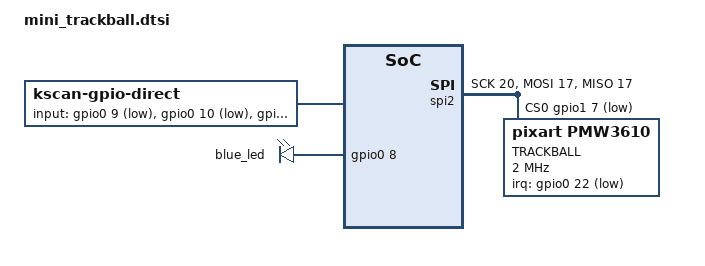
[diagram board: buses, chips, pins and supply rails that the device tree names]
/*
 * Copyright (c) 2020 The ZMK Contributors
 *
 * SPDX-License-Identifier: MIT
 */

#include <dt-bindings/zmk/matrix_transform.h>

/* blade-specific: common settings */ 
/ {

	chosen: chosen {
		zmk,kscan = &kscan;
		zmk,matrix_transform = &default_transform;
	};

/* global matrix transform */
	default_transform: keymap_transform_0 {
		compatible = "zmk,matrix-transform";
		columns = <4>;
		rows = <1>;
		map = <
RC(0,0) RC(0,1) RC(0,2) RC(0,3)
		>;

	};

  /* Scan matrix declaration */
	kscan: kscan {
		compatible = "zmk,kscan-gpio-direct";
		label = "KSCAN";
		input-gpios
		= <&gpio0 9 (GPIO_ACTIVE_LOW | GPIO_PULL_UP)>
		, <&gpio0 10 (GPIO_ACTIVE_LOW | GPIO_PULL_UP)>
		, <&gpio0 29 (GPIO_ACTIVE_LOW | GPIO_PULL_UP)>
		, <&gpio0 31 (GPIO_ACTIVE_LOW | GPIO_PULL_UP)>;
	};

  /* Configure trackballs (either split can have the trackball) */
	trackballs {
		compatible = "zmk,keymap-trackballs";
		trackballs = <&trackball>;
	};
};

/* Declare the trackball */
&spi2 {
  compatible = "nordic,nrf-spim";
  status = "okay";

  sck-pin = <20>;
  mosi-pin = <17>;
  miso-pin = <17>; // same as mosi (3-wire spi)
  cs-gpios = <&gpio1 7 GPIO_ACTIVE_LOW>;

  trackball: trackball@0 {
    compatible = "pixart,pmw3610";
    status = "okay";
    reg = <0>;
    label = "TRACKBALL";
    irq-gpios = <&gpio0 22 (GPIO_ACTIVE_LOW | GPIO_PULL_UP)>;
    spi-max-frequency = <2000000>;
    duplex = <2048>; // required by 3-wire spi
  };
};

/* overrides nrfmacro.dts defaults */ 
&blue_led {
  gpios = <&gpio0 8 GPIO_ACTIVE_HIGH>;
};

&vcc_ctrl {
  status = "disabled";
};

&vbatt {
	io-channels = <&adc 3>;
  output-ohms = <10000000>;
	full-ohms = <(4000000 + 10000000)>;
};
